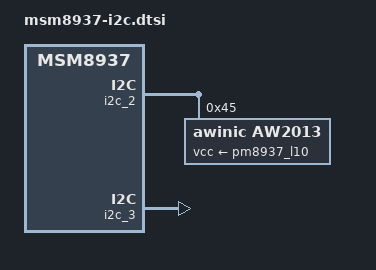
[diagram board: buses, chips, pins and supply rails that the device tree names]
#include <dt-bindings/leds/common.h>

&i2c_2  {
	status = "okay";
	aw2013@45 {
		#address-cells = <1>;
		#size-cells = <0>;

		compatible = "awinic,aw2013";

		reg = <0x45>;
		vcc-supply = <&pm8937_l10>;

		led@0 {
			reg = <0>;
			led-max-microamp = <5000>;
			function = LED_FUNCTION_INDICATOR;
			color = <LED_COLOR_ID_RED>;
			label = "red";
		};
		led@1 {
			reg = <1>;
			led-max-microamp = <5000>;
			function = LED_FUNCTION_INDICATOR;
			color = <LED_COLOR_ID_GREEN>;
			label = "green";
		};
		led@2 {
			reg = <2>;
			led-max-microamp = <5000>;
			function = LED_FUNCTION_INDICATOR;
			color = <LED_COLOR_ID_BLUE>;
			label = "blue";
		};
	};
    pericom-type-c@1d {
		status="disabled";
    };
};

&i2c_3 {
	status = "okay";
	qcom,clk-freq-out = <100000>;
};
